# MM32F031xx register map
File version: 1.3
Registers are 32-bit, read-write, reset 0x0 unless marked. A register's access mark holds for its fields unless they carry their own. Offsets are from the block's base; [hi:lo] are bit positions; {n}, {i} and the like mark numbered series.

## TIM2 — General purpose timer
Base 0x40000000
Same registers: TIM3 0x40000400
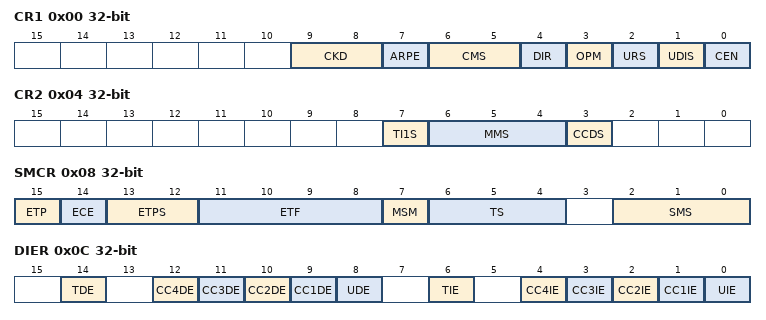
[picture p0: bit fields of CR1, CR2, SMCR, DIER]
0x00 CR1
  [9:8] CKD — Clock division
  [7] ARPE — Auto-reload preload enable
  [6:5] CMS — Center-aligned mode selection
  [4] DIR — Direction
  [3] OPM — One pulse mode
  [2] URS — Update request source
  [1] UDIS — Update disable
  [0] CEN — Counter enable
0x04 CR2
  [7] TI1S — TI1 selection
  [6:4] MMS — Master mode selection
  [3] CCDS — Capture/Compare DMA selection
0x08 SMCR
  [15] ETP — External trigger polarity
  [14] ECE — External clock enable
  [13:12] ETPS — External trigger prescaler
  [11:8] ETF — External trigger filter
  [7] MSM — Master/slave mode
  [6:4] TS — Trigger selection
  [2:0] SMS — Slave mode selection
0x0C DIER
  [14] TDE — Trigger DMA request enable
  [n+8] CC{n}DE (n=1..4) — Capture/Compare {n} DMA request enable
  [8] UDE — Update DMA request enable
  [6] TIE — Trigger interrupt enable
  [n] CC{n}IE (n=1..4) — Capture/Compare {n} interrupt enable
  [0] UIE — Update interrupt enable
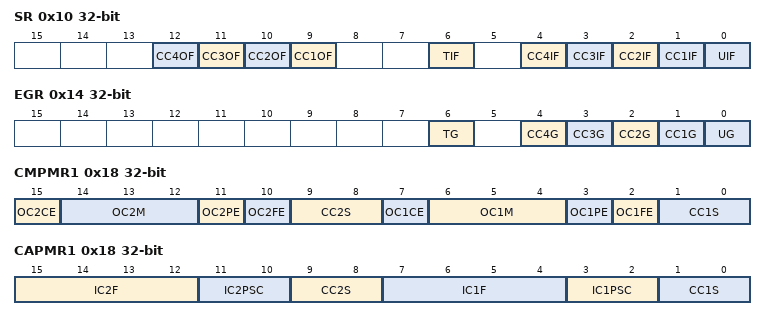
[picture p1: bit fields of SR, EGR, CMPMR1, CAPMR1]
0x10 SR
  [n+8] CC{n}OF (n=1..4) — Capture/Compare {n} overcapture flag
  [6] TIF — Trigger interrupt flag
  [n] CC{n}IF (n=1..4) — Capture/Compare {n} interrupt flag
  [0] UIF — Update interrupt flag
0x14 EGR wo
  [6] TG — Trigger generation
  [n] CC{n}G (n=1..4) — Capture/compare {n} generation
  [0] UG — Update generation
0x18 CMPMR1
  [15] OC2CE — Output compare 2 clear enable
  [14:12] OC2M — Output compare 2 mode
  [11] OC2PE — Output compare 2 preload enable
  [10] OC2FE — Output compare 2 fast enable
  [9:8] CC2S — Capture/Compare 2 selection
  [7] OC1CE — Output compare 1 clear enable
  [6:4] OC1M — Output compare 1 enable
  [3] OC1PE — Output compare 1 preload enable
  [2] OC1FE — Output compare 1 fast enable
  [1:0] CC1S — Capture/Compare 1 selection
0x18 CAPMR1
  [15:12] IC2F — Input capture 2 filter
  [11:10] IC2PSC — input capture 2 prescaler
  [9:8] CC2S — Capture/compare 2 selection
  [7:4] IC1F — Input capture 1 filter
  [3:2] IC1PSC — Input capture 1 prescaler
  [1:0] CC1S — Capture/Compare 1 selection
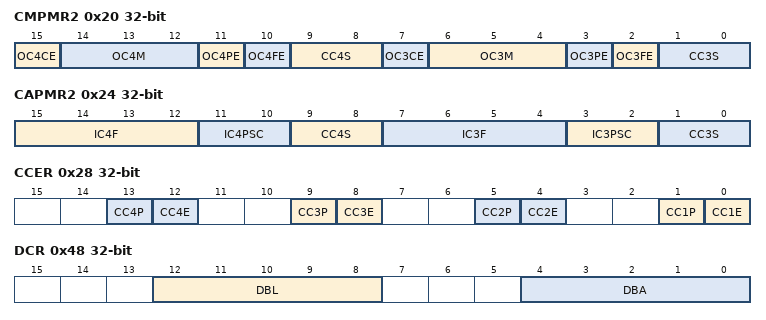
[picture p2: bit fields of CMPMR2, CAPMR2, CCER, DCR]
0x20 CMPMR2
  [15] OC4CE — Output compare 4 clear enable
  [14:12] OC4M — Output compare 4 mode
  [11] OC4PE — Output compare 4 preload enable
  [10] OC4FE — Output compare 4 fast enable
  [9:8] CC4S — Capture/Compare 4 selection
  [7] OC3CE — Output compare 3 clear enable
  [6:4] OC3M — Output compare 3 mode
  [3] OC3PE — Output compare 3 preload enable
  [2] OC3FE — Output compare 3 fast enable
  [1:0] CC3S — Capture/Compare 3 selection
0x24 CAPMR2
  [15:12] IC4F — Input capture 4 filter
  [11:10] IC4PSC — input capture 4 prescaler
  [9:8] CC4S — Capture/compare 4 selection
  [7:4] IC3F — Input capture 3 filter
  [3:2] IC3PSC — Input capture 3 prescaler
  [1:0] CC3S — Capture/Compare 3 selection
0x28 CCER wo
  [4n-3] CC{n}P (n=1..4) — Capture/Compare {n} output polarity
  [4n-4] CC{n}E (n=1..4) — Capture/Compare {n} output enable
0x2C CNT
  [15:0] CNT — Counter value
0x30 PSC
  [15:0] PSC — Prescaler value
0x34 ARR
  [15:0] ARR — Auto reload value
{0x34+4i} CCR{i} (i=1..4)
  [15:0] CCR{i} — Capture/Compare {i} value
0x48 DCR
  [12:8] DBL — DMA burst length
  [4:0] DBA — DMA base address
0x4C DMAR
  [15:0] DMAB — DMA register for burst accesses

## TIM14 — Advanced timer
Base 0x40014000
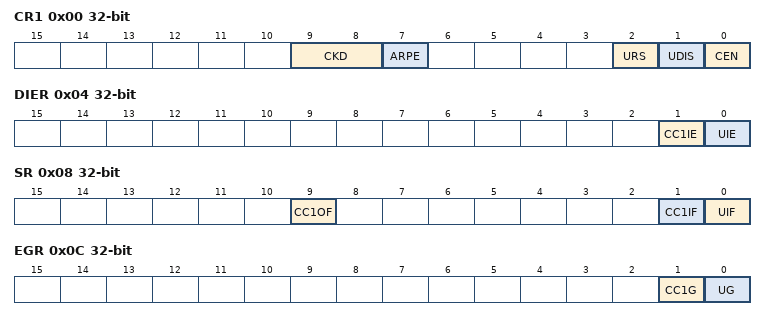
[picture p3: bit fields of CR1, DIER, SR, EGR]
0x00 CR1
  [9:8] CKD, [7] ARPE, [2] URS, [1] UDIS, [0] CEN
0x04 DIER
  [1] CC1IE, [0] UIE
0x08 SR
  [9] CC1OF, [1] CC1IF, [0] UIF
0x0C EGR wo
  [1] CC1G, [0] UG
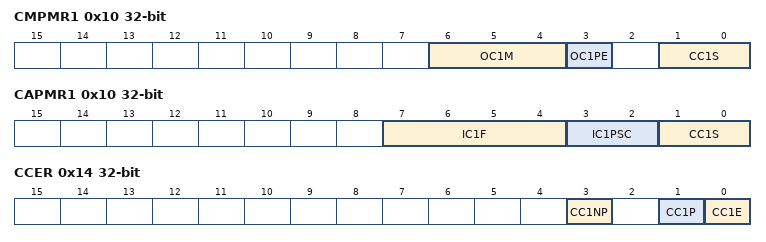
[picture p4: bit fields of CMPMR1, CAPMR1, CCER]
0x10 CMPMR1
  [6:4] OC1M, [3] OC1PE, [1:0] CC1S
0x10 CAPMR1
  [7:4] IC1F, [3:2] IC1PSC, [1:0] CC1S
0x14 CCER
  [3] CC1NP, [1] CC1P, [0] CC1E
0x18 CNT
  [15:0] CNT
0x1C PSC
  [15:0] PSE
0x20 ARR
  [15:0] ARR
0x24 CRR1
  [15:0] CRR1

## TIM16 — Advanced timer
Base 0x40014400
Same registers: TIM17 0x40014800
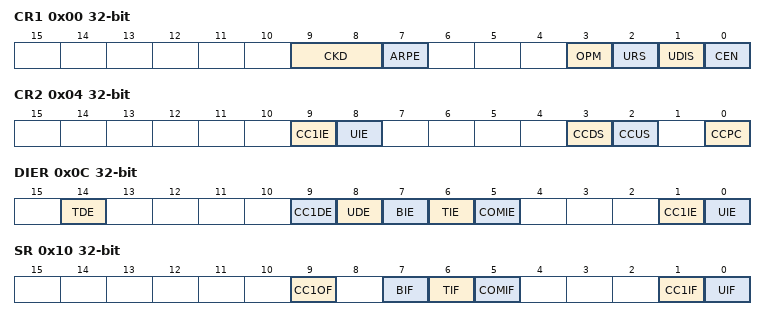
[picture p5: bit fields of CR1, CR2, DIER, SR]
0x00 CR1
  [9:8] CKD, [7] ARPE, [3] OPM, [2] URS, [1] UDIS, [0] CEN
0x04 CR2 — CR3
  [9] CC1IE, [8] UIE, [3] CCDS, [2] CCUS, [0] CCPC
0x0C DIER
  [14] TDE, [9] CC1DE, [8] UDE, [7] BIE, [6] TIE, [5] COMIE, [1] CC1IE, [0] UIE
0x10 SR
  [9] CC1OF, [7] BIF, [6] TIF, [5] COMIF, [1] CC1IF, [0] UIF
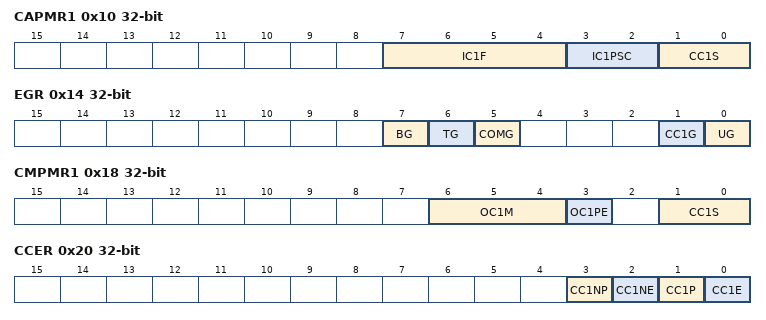
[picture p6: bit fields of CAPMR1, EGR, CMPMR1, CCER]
0x10 CAPMR1
  [7:4] IC1F, [3:2] IC1PSC, [1:0] CC1S
0x14 EGR wo
  [7] BG, [6] TG, [5] COMG, [1] CC1G, [0] UG
0x18 CMPMR1
  [6:4] OC1M, [3] OC1PE, [1:0] CC1S
0x20 CCER
  [3] CC1NP, [2] CC1NE, [1] CC1P, [0] CC1E
0x24 CNT
  [15:0] CNT
0x28 PSC
  [15:0] PSC
0x2C ARR
  [15:0] ARR
0x30 RCR
  [7:0] REP
0x34 CCR1 — CCR2
  [15:0] CCR1
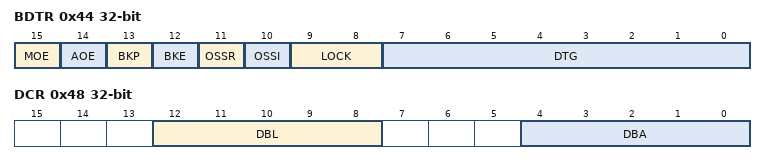
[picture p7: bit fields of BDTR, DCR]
0x44 BDTR
  [15] MOE, [14] AOE, [13] BKP, [12] BKE, [11] OSSR, [10] OSSI, [9:8] LOCK, [7:0] DTG
0x48 DCR
  [12:8] DBL, [4:0] DBA
0x4C DMAR
  [15:0] DMAB

## FLASH
Base 0x40022000
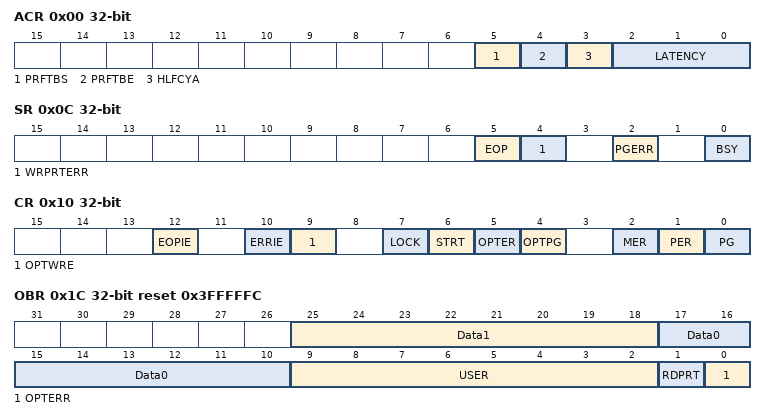
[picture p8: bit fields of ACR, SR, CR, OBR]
0x00 ACR
  [5] PRFTBS — Prefetch buffer status
  [4] PRFTBE — Prefetch buffer enable
  [3] HLFCYA — Flash half cycle access enable
  [2:0] LATENCY
0x04 KEYR wo
  [31:0] FKEYR — Flash key
0x08 OPTKEYR wo
  [31:0] OPTKEYR — Option byte key
0x0C SR
  [5] EOP — End of operation
  [4] WRPRTERR — Write protection error
  [2] PGERR — Programming error
  [0] BSY — Busy
0x10 CR
  [12] EOPIE — End of operation interrupt enable
  [10] ERRIE — Error interrupt enable
  [9] OPTWRE — Option byte write enable
  [7] LOCK
  [6] STRT — Start
  [5] OPTER — Option byte erase
  [4] OPTPG — Option byte programming
  [2] MER — Mass erase
  [1] PER — Page erase
  [0] PG — Programming
0x14 AR wo
  [31:0] FAR — Flash Address
0x1C OBR ro reset 0x3FFFFFC
  [25:18] Data1
  [17:10] Data0
  [9:2] USER — User option bytes
  [1] RDPRT — Read protection level status
  [0] OPTERR — Option byte error
0x20 WRPR ro reset 0xFFFFFFFF
  [31:0] WRP — Write protect

## DBG — Debug support
Base 0xE0042000
0x00 MCU ro
  [31:0] DEV_ID — Device identifier
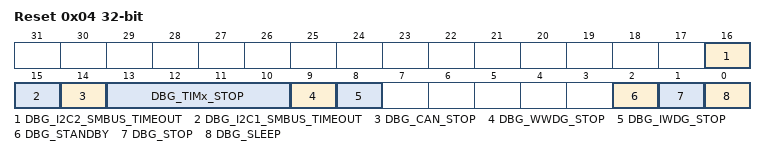
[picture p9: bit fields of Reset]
0x04 Reset wo
  [16] DBG_I2C2_SMBUS_TIMEOUT — SMBUS timeout mode stopped when Core is halted
  [15] DBG_I2C1_SMBUS_TIMEOUT — SMBUS timeout mode stopped when Core is halted
  [14] DBG_CAN_STOP — Debug CAN stopped when core is halted
  [13:10] DBG_TIMx_STOP — TIMx counter stopped when core is halted
  [9] DBG_WWDG_STOP — Debug window watchdog stopped when core is halted
  [8] DBG_IWDG_STOP — Debug independent watchdog stopped when core is halted
  [2] DBG_STANDBY — Debug Standby mode
  [1] DBG_STOP — Debug Stop mode
  [0] DBG_SLEEP — Debug Sleep mode
